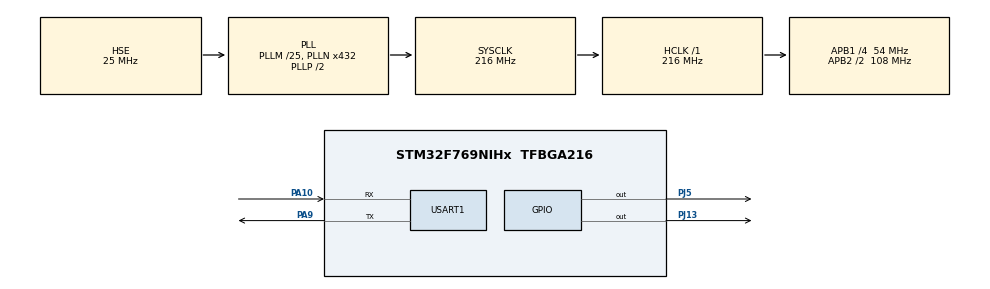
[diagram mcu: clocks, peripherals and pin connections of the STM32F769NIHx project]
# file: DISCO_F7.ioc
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CORTEX_M7.default_mode_Activation=1
FREERTOS.Tasks01=defaultTask,24,256,StartDefaultTask,Default,NULL,Dynamic,NULL,NULL
Mcu.Family=STM32F7
Mcu.Name=STM32F769NIHx
Mcu.Package=TFBGA216
NVIC.PriorityGroup=NVIC_PRIORITYGROUP_4
NVIC.USART1_IRQn=true\:5\:0\:false\:false\:true\:true\:true\:true\:true
PA10.Mode=Asynchronous
PA10.Signal=USART1_RX
PA9.Mode=Asynchronous
PA9.Signal=USART1_TX
PC14/OSC32_IN.Mode=LSE-External-Oscillator
PC14/OSC32_IN.Signal=RCC_OSC32_IN
PC15/OSC32_OUT.Mode=LSE-External-Oscillator
PC15/OSC32_OUT.Signal=RCC_OSC32_OUT
PH0/OSC_IN.Mode=HSE-External-Oscillator
PH0/OSC_IN.Signal=RCC_OSC_IN
PH1/OSC_OUT.Mode=HSE-External-Oscillator
PH1/OSC_OUT.Signal=RCC_OSC_OUT
PJ13.Signal=GPIO_Output
PJ5.Signal=GPIO_Output
ProjectManager.HeapSize=0x200
ProjectManager.StackSize=0x400
ProjectManager.TargetToolchain=STM32CubeIDE
RCC.AHBFreq_Value=216000000
RCC.APB1CLKDivider=RCC_HCLK_DIV4
RCC.APB1Freq_Value=54000000
RCC.APB1TimFreq_Value=108000000
RCC.APB2CLKDivider=RCC_HCLK_DIV2
RCC.APB2Freq_Value=108000000
RCC.APB2TimFreq_Value=216000000
RCC.CortexFreq_Value=216000000
RCC.HCLKFreq_Value=216000000
RCC.HSE_VALUE=25000000
RCC.HSI_VALUE=16000000
RCC.PLLM=25
RCC.PLLN=432
RCC.PLLSourceVirtual=RCC_PLLSOURCE_HSE
RCC.SYSCLKFreq_VALUE=216000000
RCC.SYSCLKSource=RCC_SYSCLKSOURCE_PLLCLK
RCC.USBFreq_Value=216000000
RCC.VCOOutputFreq_Value=432000000
USART1.VirtualMode-Asynchronous=VM_ASYNC
VP_FREERTOS_VS_CMSIS_V2.Mode=CMSIS_V2
board=custom

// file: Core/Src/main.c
/* USER CODE BEGIN Header */
/**
  ******************************************************************************
  * @file           : main.c
  * @brief          : Main program body
  ******************************************************************************
  * @attention
  *
  * Copyright (c) 2026 STMicroelectronics.
  * All rights reserved.
  *
  * This software is licensed under terms that can be found in the LICENSE file
  * in the root directory of this software component.
  * If no LICENSE file comes with this software, it is provided AS-IS.
  *
  ******************************************************************************
  */
/* USER CODE END Header */
#include "main.h"
#include "cmsis_os.h"

/* USER CODE BEGIN Includes */
#include "cliDebug.h"
/* USER CODE END Includes */

UART_HandleTypeDef huart1;

/* Definitions for defaultTask */
osThreadId_t defaultTaskHandle;
const osThreadAttr_t defaultTask_attributes = {
  .name = "defaultTask",
  .stack_size = 256 * 4,
  .priority = (osPriority_t) osPriorityNormal,
};

void SystemClock_Config(void);
static void MPU_Config(void);
static void MX_GPIO_Init(void);
static void MX_USART1_UART_Init(void);
void StartDefaultTask(void *argument);

int main(void)
{

  /* MPU Configuration--------------------------------------------------------*/
  MPU_Config();

  /* MCU Configuration--------------------------------------------------------*/

  /* Reset of all peripherals, Initializes the Flash interface and the Systick. */
  HAL_Init();

  /* Configure the system clock */
  SystemClock_Config();

  /* Initialize all configured peripherals */
  MX_GPIO_Init();
  MX_USART1_UART_Init();

  /* Init scheduler */
  osKernelInitialize();

  /* Create the thread(s) */
  /* creation of defaultTask */
  defaultTaskHandle = osThreadNew(StartDefaultTask, NULL, &defaultTask_attributes);

  /* USER CODE BEGIN RTOS_THREADS */
  /* add threads, ... */
  cliTaskInit();
  /* USER CODE END RTOS_THREADS */

  /* Start scheduler */
  osKernelStart();

  /* We should never get here as control is now taken by the scheduler */

  /* Infinite loop */
  while (1)
  {

  }
}

void SystemClock_Config(void)
{
  RCC_OscInitTypeDef RCC_OscInitStruct = {0};
  RCC_ClkInitTypeDef RCC_ClkInitStruct = {0};

  /** Configure LSE Drive Capability
  */
  HAL_PWR_EnableBkUpAccess();

  /** Configure the main internal regulator output voltage
  */
  __HAL_RCC_PWR_CLK_ENABLE();
  __HAL_PWR_VOLTAGESCALING_CONFIG(PWR_REGULATOR_VOLTAGE_SCALE1);

  /** Initializes the RCC Oscillators according to the specified parameters
  * in the RCC_OscInitTypeDef structure.
  */
  RCC_OscInitStruct.OscillatorType = RCC_OSCILLATORTYPE_HSE;
  RCC_OscInitStruct.HSEState = RCC_HSE_ON;
  RCC_OscInitStruct.PLL.PLLState = RCC_PLL_ON;
  RCC_OscInitStruct.PLL.PLLSource = RCC_PLLSOURCE_HSE;
  RCC_OscInitStruct.PLL.PLLM = 25;
  RCC_OscInitStruct.PLL.PLLN = 432;
  RCC_OscInitStruct.PLL.PLLP = RCC_PLLP_DIV2;
  RCC_OscInitStruct.PLL.PLLQ = 2;
  RCC_OscInitStruct.PLL.PLLR = 2;
  if (HAL_RCC_OscConfig(&RCC_OscInitStruct) != HAL_OK)
  {
    Error_Handler();
  }

  /** Activate the Over-Drive mode
  */
  if (HAL_PWREx_EnableOverDrive() != HAL_OK)
  {
    Error_Handler();
  }

  /** Initializes the CPU, AHB and APB buses clocks
  */
  RCC_ClkInitStruct.ClockType = RCC_CLOCKTYPE_HCLK|RCC_CLOCKTYPE_SYSCLK
                              |RCC_CLOCKTYPE_PCLK1|RCC_CLOCKTYPE_PCLK2;
  RCC_ClkInitStruct.SYSCLKSource = RCC_SYSCLKSOURCE_PLLCLK;
  RCC_ClkInitStruct.AHBCLKDivider = RCC_SYSCLK_DIV1;
  RCC_ClkInitStruct.APB1CLKDivider = RCC_HCLK_DIV4;
  RCC_ClkInitStruct.APB2CLKDivider = RCC_HCLK_DIV2;

  if (HAL_RCC_ClockConfig(&RCC_ClkInitStruct, FLASH_LATENCY_7) != HAL_OK)
  {
    Error_Handler();
  }
}

static void MX_USART1_UART_Init(void)
{

  huart1.Instance = USART1;
  huart1.Init.BaudRate = 115200;
  huart1.Init.WordLength = UART_WORDLENGTH_8B;
  huart1.Init.StopBits = UART_STOPBITS_1;
  huart1.Init.Parity = UART_PARITY_NONE;
  huart1.Init.Mode = UART_MODE_TX_RX;
  huart1.Init.HwFlowCtl = UART_HWCONTROL_NONE;
  huart1.Init.OverSampling = UART_OVERSAMPLING_16;
  huart1.Init.OneBitSampling = UART_ONE_BIT_SAMPLE_DISABLE;
  huart1.AdvancedInit.AdvFeatureInit = UART_ADVFEATURE_NO_INIT;
  if (HAL_UART_Init(&huart1) != HAL_OK)
  {
    Error_Handler();
  }

}

static void MX_GPIO_Init(void)
{
  GPIO_InitTypeDef GPIO_InitStruct = {0};

  /* GPIO Ports Clock Enable */
  __HAL_RCC_GPIOJ_CLK_ENABLE();
  __HAL_RCC_GPIOA_CLK_ENABLE();
  __HAL_RCC_GPIOC_CLK_ENABLE();
  __HAL_RCC_GPIOH_CLK_ENABLE();

  /*Configure GPIO pin Output Level */
  HAL_GPIO_WritePin(GPIOJ, GPIO_PIN_13|GPIO_PIN_5, GPIO_PIN_RESET);

  /*Configure GPIO pins : PJ13 PJ5 */
  GPIO_InitStruct.Pin = GPIO_PIN_13|GPIO_PIN_5;
  GPIO_InitStruct.Mode = GPIO_MODE_OUTPUT_PP;
  GPIO_InitStruct.Pull = GPIO_NOPULL;
  GPIO_InitStruct.Speed = GPIO_SPEED_FREQ_LOW;
  HAL_GPIO_Init(GPIOJ, &GPIO_InitStruct);

}

void StartDefaultTask(void *argument)
{
  /* USER CODE BEGIN 5 */
  /* Infinite loop */
	uint8_t testStr[] = "\r\nMesg From Default Task.";
  for(;;)
  {
		HAL_GPIO_WritePin(GPIOJ, GPIO_PIN_13|GPIO_PIN_5, GPIO_PIN_RESET);
		//HAL_UART_Transmit_IT( &huart1, testStr, 25 );
	    osDelay(1000);
		HAL_GPIO_WritePin(GPIOJ, GPIO_PIN_13|GPIO_PIN_5, GPIO_PIN_SET);
	    osDelay(1000);
  }
  /* USER CODE END 5 */
}

 /* MPU Configuration */

void MPU_Config(void)
{
  MPU_Region_InitTypeDef MPU_InitStruct = {0};

  /* Disables the MPU */
  HAL_MPU_Disable();

  /** Initializes and configures the Region and the memory to be protected
  */
  MPU_InitStruct.Enable = MPU_REGION_ENABLE;
  MPU_InitStruct.Number = MPU_REGION_NUMBER0;
  MPU_InitStruct.BaseAddress = 0x0;
  MPU_InitStruct.Size = MPU_REGION_SIZE_4GB;
  MPU_InitStruct.SubRegionDisable = 0x87;
  MPU_InitStruct.TypeExtField = MPU_TEX_LEVEL0;
  MPU_InitStruct.AccessPermission = MPU_REGION_NO_ACCESS;
  MPU_InitStruct.DisableExec = MPU_INSTRUCTION_ACCESS_DISABLE;
  MPU_InitStruct.IsShareable = MPU_ACCESS_SHAREABLE;
  MPU_InitStruct.IsCacheable = MPU_ACCESS_NOT_CACHEABLE;
  MPU_InitStruct.IsBufferable = MPU_ACCESS_NOT_BUFFERABLE;

  HAL_MPU_ConfigRegion(&MPU_InitStruct);
  /* Enables the MPU */
  HAL_MPU_Enable(MPU_PRIVILEGED_DEFAULT);

}

void Error_Handler(void)
{
  __disable_irq();
  while (1)
  {
  }
}
